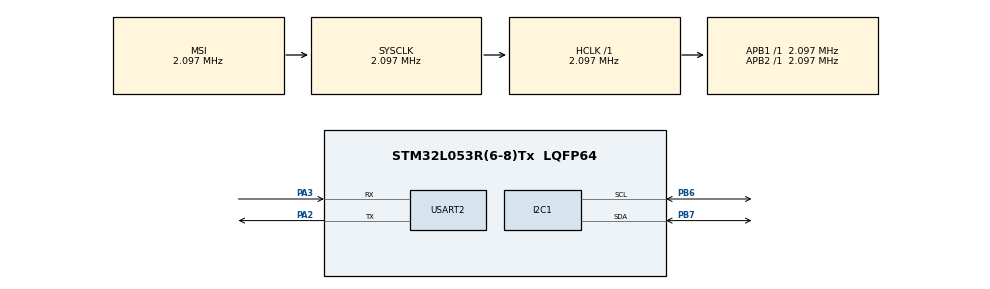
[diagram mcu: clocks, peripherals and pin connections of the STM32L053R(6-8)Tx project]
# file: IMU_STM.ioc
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Mcu.Family=STM32L0
Mcu.Name=STM32L053R(6-8)Tx
Mcu.Package=LQFP64
PA2.Mode=Asynchronous
PA2.Signal=USART2_TX
PA3.Mode=Asynchronous
PA3.Signal=USART2_RX
PB6.Mode=I2C
PB6.Signal=I2C1_SCL
PB7.Mode=I2C
PB7.Signal=I2C1_SDA
ProjectManager.HeapSize=0x200
ProjectManager.StackSize=0x400
ProjectManager.TargetToolchain=STM32CubeIDE
RCC.AHBFreq_Value=2097000
RCC.APB1Freq_Value=2097000
RCC.APB1TimFreq_Value=2097000
RCC.APB2Freq_Value=2097000
RCC.APB2TimFreq_Value=2097000
RCC.HSE_VALUE=8000000
RCC.HSI16_VALUE=16000000
RCC.HSI48_VALUE=48000000
RCC.HSI_VALUE=16000000
RCC.LSE_VALUE=32768
RCC.MSI_VALUE=2097000
RCC.SYSCLKFreq_VALUE=2097000
RCC.VCOOutputFreq_Value=48000000
USART2.VirtualMode-Asynchronous=VM_ASYNC
board=custom

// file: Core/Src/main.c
/* USER CODE BEGIN Header */
/**
 ******************************************************************************
 * @file           : main.c
 * @brief          : Main program body
 ******************************************************************************
 * @attention
 *
 * Copyright (c) 2022 STMicroelectronics.
 * All rights reserved.
 *
 * This software is licensed under terms that can be found in the LICENSE file
 * in the root directory of this software component.
 * If no LICENSE file comes with this software, it is provided AS-IS.
 *
 ******************************************************************************
 */
/* USER CODE END Header */
#include "main.h"

/* USER CODE BEGIN Includes */
#include "LSM303AGR.h"
/* USER CODE END Includes */

I2C_HandleTypeDef hi2c1;

UART_HandleTypeDef huart2;

LSM303AGR lsm303agr;

void SystemClock_Config(void);
static void MX_GPIO_Init(void);
static void MX_I2C1_Init(void);
static void MX_USART2_UART_Init(void);
/* USER CODE BEGIN PFP */
#define PUTCHAR_PROTOTYPE int __io_putchar(int ch)
/* USER CODE END PFP */

int main(void) {

	/* MCU Configuration--------------------------------------------------------*/

	/* Reset of all peripherals, Initializes the Flash interface and the Systick. */
	HAL_Init();

	/* Configure the system clock */
	SystemClock_Config();

	/* Initialize all configured peripherals */
	MX_GPIO_Init();
	MX_I2C1_Init();
	MX_USART2_UART_Init();
	/* USER CODE BEGIN 2 */
	LSM303AGR_Initialise(&lsm303agr, &hi2c1);
	/* USER CODE END 2 */

	/* Infinite loop */
	while (1) {
		uint8_t errorcode;
		errorcode = LSM303AGR_ReadTemperature(&lsm303agr);
		if (errorcode == 0) {
			printf("\nTemperature: %3.1f °C\r", lsm303agr.temp_C);
		} else {
			printf("Errorcode: %d", errorcode);

		}
		errorcode = LSM303AGR_ReadMagnetometer(&lsm303agr);
		if (errorcode == 0) {
			printf("\nMagnetometer (X,Y,Z): %3.2f, %3.2f, %3.2f\r",
					lsm303agr.mag[0], lsm303agr.mag[1], lsm303agr.mag[2]);
			printf("\nAlignment: %3.1f\r", lsm303agr.alignment);
			printf("\nTotal B-Field: %3.2f Gauss\r",sqrt(lsm303agr.mag[0]*lsm303agr.mag[0]+lsm303agr.mag[1]*lsm303agr.mag[1]+lsm303agr.mag[2]*lsm303agr.mag[2]));
		} else {
			printf("Errorcode: %d", errorcode);

		}

		errorcode = LSM303AGR_ReadAcceleration(&lsm303agr);
		if (errorcode == 0) {
			printf("\nAccelerometer (X,Y,Z): %4.2f, %4.2f, %4.2f\r",
					lsm303agr.acc[0], lsm303agr.acc[1], lsm303agr.acc[2]);
			printf("\nPitch: %3.2f, Roll: %3.2f\r", lsm303agr.pitch, lsm303agr.roll);
			printf("\nTotal Acc: %3.2f g\r",sqrt(lsm303agr.acc[0]*lsm303agr.acc[0]+lsm303agr.acc[1]*lsm303agr.acc[1]+lsm303agr.acc[2]*lsm303agr.acc[2]));
		} else {
			printf("Errorcode: %d", errorcode);

		}
		HAL_Delay(3000);
	}
}

void SystemClock_Config(void) {
	RCC_OscInitTypeDef RCC_OscInitStruct = { 0 };
	RCC_ClkInitTypeDef RCC_ClkInitStruct = { 0 };
	RCC_PeriphCLKInitTypeDef PeriphClkInit = { 0 };

	/** Configure the main internal regulator output voltage
	 */
	__HAL_PWR_VOLTAGESCALING_CONFIG(PWR_REGULATOR_VOLTAGE_SCALE1);

	/** Initializes the RCC Oscillators according to the specified parameters
	 * in the RCC_OscInitTypeDef structure.
	 */
	RCC_OscInitStruct.OscillatorType = RCC_OSCILLATORTYPE_MSI;
	RCC_OscInitStruct.MSIState = RCC_MSI_ON;
	RCC_OscInitStruct.MSICalibrationValue = 0;
	RCC_OscInitStruct.MSIClockRange = RCC_MSIRANGE_5;
	RCC_OscInitStruct.PLL.PLLState = RCC_PLL_NONE;
	if (HAL_RCC_OscConfig(&RCC_OscInitStruct) != HAL_OK) {
		Error_Handler();
	}

	/** Initializes the CPU, AHB and APB buses clocks
	 */
	RCC_ClkInitStruct.ClockType = RCC_CLOCKTYPE_HCLK | RCC_CLOCKTYPE_SYSCLK
			| RCC_CLOCKTYPE_PCLK1 | RCC_CLOCKTYPE_PCLK2;
	RCC_ClkInitStruct.SYSCLKSource = RCC_SYSCLKSOURCE_MSI;
	RCC_ClkInitStruct.AHBCLKDivider = RCC_SYSCLK_DIV1;
	RCC_ClkInitStruct.APB1CLKDivider = RCC_HCLK_DIV1;
	RCC_ClkInitStruct.APB2CLKDivider = RCC_HCLK_DIV1;

	if (HAL_RCC_ClockConfig(&RCC_ClkInitStruct, FLASH_LATENCY_0) != HAL_OK) {
		Error_Handler();
	}
	PeriphClkInit.PeriphClockSelection = RCC_PERIPHCLK_USART2
			| RCC_PERIPHCLK_I2C1;
	PeriphClkInit.Usart2ClockSelection = RCC_USART2CLKSOURCE_PCLK1;
	PeriphClkInit.I2c1ClockSelection = RCC_I2C1CLKSOURCE_PCLK1;
	if (HAL_RCCEx_PeriphCLKConfig(&PeriphClkInit) != HAL_OK) {
		Error_Handler();
	}
}

static void MX_I2C1_Init(void) {

	hi2c1.Instance = I2C1;
	hi2c1.Init.Timing = 0x00000708;
	hi2c1.Init.OwnAddress1 = 0;
	hi2c1.Init.AddressingMode = I2C_ADDRESSINGMODE_7BIT;
	hi2c1.Init.DualAddressMode = I2C_DUALADDRESS_DISABLE;
	hi2c1.Init.OwnAddress2 = 0;
	hi2c1.Init.OwnAddress2Masks = I2C_OA2_NOMASK;
	hi2c1.Init.GeneralCallMode = I2C_GENERALCALL_DISABLE;
	hi2c1.Init.NoStretchMode = I2C_NOSTRETCH_DISABLE;
	if (HAL_I2C_Init(&hi2c1) != HAL_OK) {
		Error_Handler();
	}

	/** Configure Analogue filter
	 */
	if (HAL_I2CEx_ConfigAnalogFilter(&hi2c1, I2C_ANALOGFILTER_ENABLE)
			!= HAL_OK) {
		Error_Handler();
	}

	/** Configure Digital filter
	 */
	if (HAL_I2CEx_ConfigDigitalFilter(&hi2c1, 0) != HAL_OK) {
		Error_Handler();
	}

}

static void MX_USART2_UART_Init(void) {

	huart2.Instance = USART2;
	huart2.Init.BaudRate = 115200;
	huart2.Init.WordLength = UART_WORDLENGTH_8B;
	huart2.Init.StopBits = UART_STOPBITS_1;
	huart2.Init.Parity = UART_PARITY_NONE;
	huart2.Init.Mode = UART_MODE_TX_RX;
	huart2.Init.HwFlowCtl = UART_HWCONTROL_NONE;
	huart2.Init.OverSampling = UART_OVERSAMPLING_16;
	huart2.Init.OneBitSampling = UART_ONE_BIT_SAMPLE_DISABLE;
	huart2.AdvancedInit.AdvFeatureInit = UART_ADVFEATURE_NO_INIT;
	if (HAL_UART_Init(&huart2) != HAL_OK) {
		Error_Handler();
	}

}

static void MX_GPIO_Init(void) {

	/* GPIO Ports Clock Enable */
	__HAL_RCC_GPIOA_CLK_ENABLE();
	__HAL_RCC_GPIOB_CLK_ENABLE();

}

/* USER CODE BEGIN 4 */
PUTCHAR_PROTOTYPE {
	/* Place your implementation of fputc here */
	/* e.g. write a character to the USART1 and Loop until the end of transmission */
	HAL_UART_Transmit(&huart2, (uint8_t*) &ch, 1, 0xFFFF);

	return ch;
}
/* USER CODE END 4 */

void Error_Handler(void) {
	__disable_irq();
	while (1) {
	}
}
